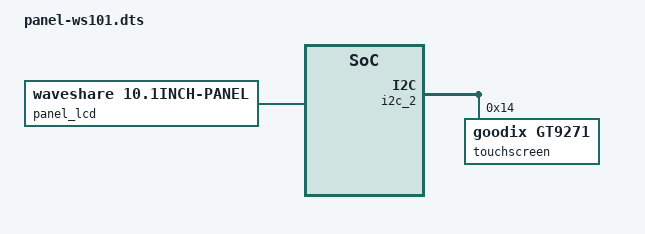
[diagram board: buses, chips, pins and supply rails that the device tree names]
// SPDX-License-Identifier: GPL-2.0
/*
 * Overlay: select the Waveshare 10.1" 1280x800 display and touch (WS-23450).
 *
 * Same result as astrial-h15-ws101.dtb, reached the other way: this one is
 * applied on top of the base tree by U-Boot at boot, so panels stay separate
 * pieces instead of multiplying into whole device trees. Select it with:
 *
 *     fw_setenv dtb_overlays '#conf-sysele_panel-ws101.dtbo' && reboot
 *
 * Note: an overlay can add or replace properties, it cannot delete them, so
 * the base tree's PWM pinctrl stays on the node. It configures a pin nothing
 * uses here, which is untidy but harmless.
 */

/dts-v1/;
/plugin/;

&panel_lcd {
    compatible = "waveshare,10.1inch-panel";
};

&i2c_2 {
    touchscreen@14 {
        compatible = "goodix,gt9271";
        reg = <0x14>;
        touchscreen-size-x = <800>;
        touchscreen-size-y = <1280>;
        touchscreen-inverted-x;
        touchscreen-swapped-x-y;
    };
};
